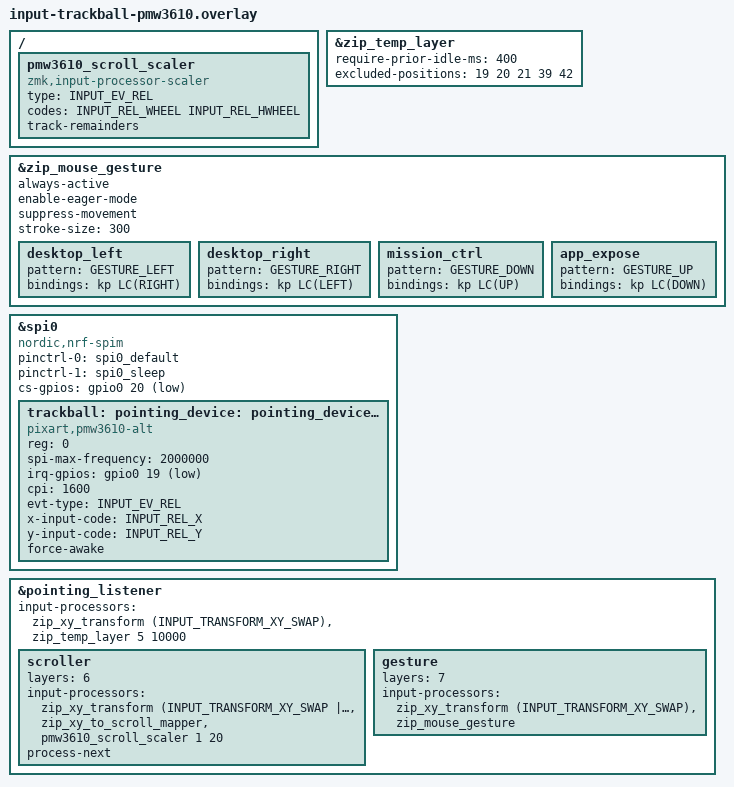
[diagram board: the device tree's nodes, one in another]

#include <dt-bindings/zmk/input_transform.h>
#include <mouse-gesture.dtsi>
#include <dt-bindings/zmk/keys.h>

/ {
    pmw3610_scroll_scaler: pmw3610_scroll_scaler {
        compatible = "zmk,input-processor-scaler";
        #input-processor-cells = <2>;
        type = <INPUT_EV_REL>;
        codes = <INPUT_REL_WHEEL INPUT_REL_HWHEEL>;
        track-remainders;
    };
};

/* zip_temp_layer に誤操作防止の設定 */
&zip_temp_layer {
    // 最後の打鍵から400ms以内にトラボを動かしてもAMLを発動させない
    require-prior-idle-ms = <400>;
    // AMLから離脱しないキー
    excluded-positions = <
        19 // J
        20 // K
        21 // L
        39 // Ctrl（WindowsではWin）
        42 // Cmd（WindowsではCtrl）
    >;
};

/* ジェスチャー機能の追加 */
&zip_mouse_gesture {
    always-active;          // 必須：キーを押さなくても、このレイヤーにいる間は認識する
    enable-eager-mode;      // 任意：動かした方向が決まった瞬間に実行する
    suppress-movement;      // 任意：レイヤー7ではカーソルを動かさない
    stroke-size = <300>;    // 任意：cpi 1600なので標準の200より少し長めに

    desktop_left  { pattern = <GESTURE_LEFT>;  bindings = <&kp LC(RIGHT)>; };
    desktop_right { pattern = <GESTURE_RIGHT>; bindings = <&kp LC(LEFT)>;  };
    mission_ctrl  { pattern = <GESTURE_DOWN>;  bindings = <&kp LC(UP)>;    };
    app_expose    { pattern = <GESTURE_UP>;    bindings = <&kp LC(DOWN)>;  };
};


&spi0 {
    status = "okay";
    compatible = "nordic,nrf-spim";
    pinctrl-0 = <&spi0_default>;
    pinctrl-1 = <&spi0_sleep>;
    pinctrl-names = "default", "sleep";
    cs-gpios = <&gpio0 20 GPIO_ACTIVE_LOW>;

    trackball: pointing_device: pointing_device@0 {
        status = "okay";
        compatible = "pixart,pmw3610-alt";
        reg = <0>;
        spi-max-frequency = <2000000>;
        irq-gpios = <&gpio0 19 (GPIO_ACTIVE_LOW | GPIO_PULL_UP)>;
        //カーソル感度
        cpi = <1600>;
        evt-type = <INPUT_EV_REL>;
        x-input-code = <INPUT_REL_X>;
        y-input-code = <INPUT_REL_Y>;
        force-awake;
    };
};

&pointing_listener {
    input-processors =
        <&zip_xy_transform (INPUT_TRANSFORM_XY_SWAP)>,
        //AMLレイヤー／タイムアウト時間
        <&zip_temp_layer 5 10000>;

    // スクロールの設定
    scroller {
        layers = <6>; // レイヤー6（scroll_layer）で発動
        input-processors =
            <&zip_xy_transform (INPUT_TRANSFORM_XY_SWAP | INPUT_TRANSFORM_Y_INVERT)>,
            <&zip_xy_to_scroll_mapper>,
            <&pmw3610_scroll_scaler 1 20>;
        process-next;
    };

    // ジェスチャーの設定
    gesture {
        layers = <7>; // レイヤー7（gesture_layer）で発動
        input-processors =
            <&zip_xy_transform (INPUT_TRANSFORM_XY_SWAP)>,
            <&zip_mouse_gesture>;
    };
};
